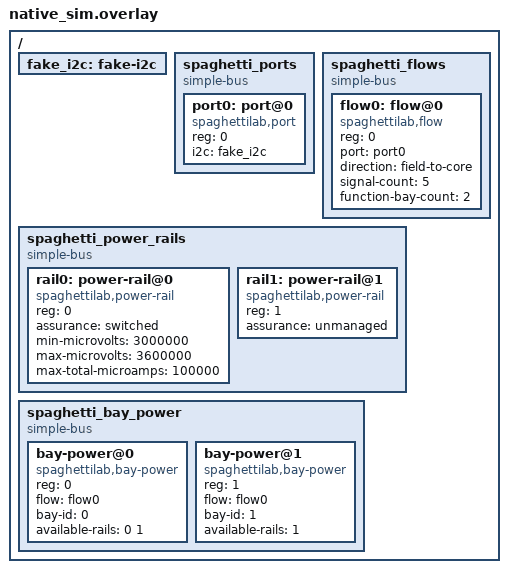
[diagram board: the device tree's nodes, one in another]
/ {
	fake_i2c: fake-i2c {
		status = "okay";
	};

	spaghetti_ports {
		compatible = "simple-bus";
		#address-cells = <1>;
		#size-cells = <0>;

		port0: port@0 {
			compatible = "spaghettilab,port";
			reg = <0>;
			i2c = <&fake_i2c>;
			status = "okay";
		};
	};

	spaghetti_flows {
		compatible = "simple-bus";
		#address-cells = <1>;
		#size-cells = <0>;

		flow0: flow@0 {
			compatible = "spaghettilab,flow";
			reg = <0>;
			port = <&port0>;
			direction = "field-to-core";
			signal-count = <5>;
			function-bay-count = <2>;
			status = "okay";
		};
	};

	spaghetti_power_rails {
		compatible = "simple-bus";
		#address-cells = <1>;
		#size-cells = <0>;

		rail0: power-rail@0 {
			compatible = "spaghettilab,power-rail";
			reg = <0>;
			assurance = "switched";
			min-microvolts = <3000000>;
			max-microvolts = <3600000>;
			max-total-microamps = <100000>;
			status = "okay";
		};

		rail1: power-rail@1 {
			compatible = "spaghettilab,power-rail";
			reg = <1>;
			assurance = "unmanaged";
			status = "okay";
		};
	};

	spaghetti_bay_power {
		compatible = "simple-bus";
		#address-cells = <1>;
		#size-cells = <0>;

		bay-power@0 {
			compatible = "spaghettilab,bay-power";
			reg = <0>;
			flow = <&flow0>;
			bay-id = <0>;
			available-rails = <0 1>;
			status = "okay";
		};

		bay-power@1 {
			compatible = "spaghettilab,bay-power";
			reg = <1>;
			flow = <&flow0>;
			bay-id = <1>;
			available-rails = <1>;
			status = "okay";
		};
	};
};
